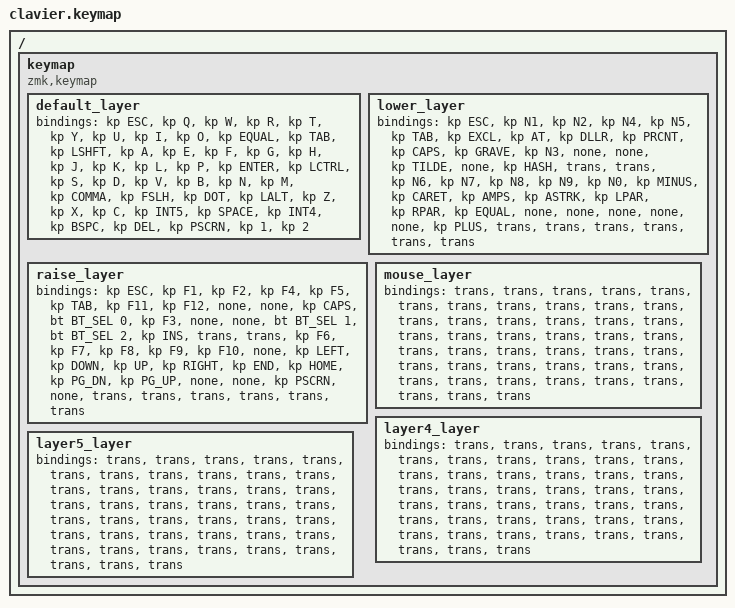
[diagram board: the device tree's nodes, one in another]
/*
 * Clavier - 回路図マトリクス基準 キーマップ定義（全6レイヤー構成）
 *
 * 💡 このファイルの読み方・メンテナンスの極意：
 * ────────────────────────────────────────────────────────────────────────
 * 「clavier.dtsi」で定義した、回路図通りの格子状住所（Row0〜3, Col0〜10）を使用します。
 * 物理的なキー配置（上段・中段・下段・親指）とは異なるため注意してください。
 * すべてのレイヤー（0〜5）の枠順（マトリクス順）は完全に統一されています。
 * 配列をカスタムする際は、必ず縦の並び（位置）を揃えて書き換えてください。
 * ────────────────────────────────────────────────────────────────────────
 */

#include <behaviors.dtsi>
#include <dt-bindings/zmk/bt.h>
#include <dt-bindings/zmk/keys.h>

// 6つのレイヤー名を定義（0 〜 5）

#define DEFAULT 0  // 0: デフォルト (QWERTY)
#define LOWER   1  // 1: 数字・記号
#define RAISE   2  // 2: ナビゲーション・BT・Fキー
#define MOUSE   3  // 3: トラックボール自動有効化（現状透過設定）
#define LAYER4  4  // 4: 拡張レイヤーA
#define LAYER5  5  // 5: 拡張レイヤーB

/ {
    keymap {
        compatible = "zmk,keymap";

        /* ＝＝＝＝＝＝＝＝＝＝ Layer 0: DEFAULT (QWERTY) ＝＝＝＝＝＝＝＝＝＝
         * 各枠の構成： [ 回路図の座標 / 物理的なキー位置 / 対応するスイッチ番号 ]
         */

        default_layer {
            bindings = <
&kp ESC  &kp Q  &kp W  &kp R  &kp T  &kp Y  &kp U  &kp I  &kp O  &kp EQUAL  &kp TAB  &kp LSHFT  &kp A  &kp E  &kp F  &kp G  &kp H  &kp J  &kp K  &kp L  &kp P  &kp ENTER  &kp LCTRL  &kp S  &kp D  &kp V  &kp B  &kp N  &kp M  &kp COMMA  &kp FSLH  &kp DOT  &kp LALT  &kp Z  &kp X  &kp C  &kp INT5  &kp SPACE  &kp INT4  &kp BSPC  &kp DEL  &kp PSCRN  &kp 1  &kp 2
            >;
        };

        /* ＝＝＝＝＝＝＝＝＝＝ Layer 1: LOWER (数字・記号) ＝＝＝＝＝＝＝＝＝＝ */

        lower_layer {
            bindings = <
&kp ESC  &kp N1  &kp N2  &kp N4  &kp N5  &kp TAB  &kp EXCL  &kp AT  &kp DLLR  &kp PRCNT  &kp CAPS  &kp GRAVE  &kp N3  &none  &none  &kp TILDE  &none  &kp HASH  &trans  &trans  &kp N6  &kp N7  &kp N8  &kp N9  &kp N0  &kp MINUS  &kp CARET  &kp AMPS  &kp ASTRK  &kp LPAR  &kp RPAR  &kp EQUAL  &none  &none  &none  &none  &none  &kp PLUS  &trans  &trans  &trans  &trans  &trans  &trans
            >;
        };

        /* ＝＝＝＝＝＝＝＝＝＝ Layer 2: RAISE (ナビゲーション・BT) ＝＝＝＝＝＝＝＝＝＝ */

        raise_layer {
            bindings = <
&kp ESC  &kp F1  &kp F2  &kp F4  &kp F5  &kp TAB  &kp F11  &kp F12  &none  &none  &kp CAPS  &bt BT_SEL 0  &kp F3  &none  &none  &bt BT_SEL 1  &bt BT_SEL 2  &kp INS  &trans  &trans  &kp F6  &kp F7  &kp F8  &kp F9  &kp F10  &none  &kp LEFT  &kp DOWN  &kp UP  &kp RIGHT  &kp END  &kp HOME  &kp PG_DN  &kp PG_UP  &none  &none  &kp PSCRN  &none  &trans  &trans  &trans  &trans  &trans  &trans
            >;
        };

        /* ＝＝＝＝＝＝＝＝＝＝ Layer 3: MOUSE (トラックボール自動有効化用) ＝＝＝＝＝＝＝＝＝＝
         * トラックボールを動かした際に自動有効化（automouse-layer = <3>）されるレイヤーです。
         */

        mouse_layer {
            bindings = <
&trans  &trans  &trans  &trans  &trans  &trans  &trans  &trans  &trans  &trans  &trans  &trans  &trans  &trans  &trans  &trans  &trans  &trans  &trans  &trans  &trans  &trans  &trans  &trans  &trans  &trans  &trans  &trans  &trans  &trans  &trans  &trans  &trans  &trans  &trans  &trans  &trans  &trans  &trans  &trans  &trans  &trans  &trans  &trans
            >;
        };

        /* ＝＝＝＝＝＝＝＝＝＝ Layer 4: 拡張用レイヤーA ＝＝＝＝＝＝＝＝＝＝
         * 任意のレイヤーです。
         */

        layer4_layer {
            bindings = <
&trans  &trans  &trans  &trans  &trans  &trans  &trans  &trans  &trans  &trans  &trans  &trans  &trans  &trans  &trans  &trans  &trans  &trans  &trans  &trans  &trans  &trans  &trans  &trans  &trans  &trans  &trans  &trans  &trans  &trans  &trans  &trans  &trans  &trans  &trans  &trans  &trans  &trans  &trans  &trans  &trans  &trans  &trans  &trans
            >;
        };

        /* ＝＝＝＝＝＝＝＝＝＝ Layer 5: 拡張用レイヤーB ＝＝＝＝＝＝＝＝＝＝
         * 任意のレイヤーです。
         */

        layer5_layer {
            bindings = <
&trans  &trans  &trans  &trans  &trans  &trans  &trans  &trans  &trans  &trans  &trans  &trans  &trans  &trans  &trans  &trans  &trans  &trans  &trans  &trans  &trans  &trans  &trans  &trans  &trans  &trans  &trans  &trans  &trans  &trans  &trans  &trans  &trans  &trans  &trans  &trans  &trans  &trans  &trans  &trans  &trans  &trans  &trans  &trans
            >;
        };
    };
};
